VERSION ""

NS_ :

BS_:

BU_: Tester BCM ECM ACC ICM
VAL_TABLE_ BrakeDecelRequestState 1 "Applied Brake" 0 "Do not Applied Brake" ;
VAL_TABLE_ ACCDriverInfoState 5 "ACC_Fault" 4 "Driver_Intervention_is_required" 3 "ACC_Active" 2 "ACC_Stanby" 1 "ACC_On" 0 "ACC_Off" ;
VAL_TABLE_ Brakeswitchstate 1 "Brake_switch_Pressed" 0 "Brake_switch_Not_pressed" ;
VAL_TABLE_ CruiseSwitchState 7 "None" 6 "Time_Gap-" 5 "Time_Gap+" 4 "Resume" 3 "Coast" 2 "Set/Accel" 1 "On" 0 "Off" ;

BO_ 1576 DiagRx: 8 ACC
 SG_ DiagRx : 0|8@1+ (1,0) [0|0] ""  Tester

BO_ 1568 DiagTx: 8 Tester
 SG_ DiagTx : 0|8@1+ (1,0) [0|0] "" Vector__XXX

BO_ 359 BCM_Info: 1 BCM
 SG_ VehicleSpeed : 0|8@1+ (1,0) [0|0] "Km/hr"  ICM,ECM,ACC

BO_ 645 ECM_Info: 1 ECM
 SG_ BrakeSwitch2 : 0|1@1+ (1,0) [0|0] ""  ACC

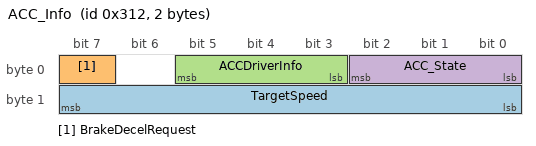
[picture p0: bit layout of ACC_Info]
BO_ 786 ACC_Info: 2 ACC
 SG_ TargetSpeed : 8|8@1+ (1,0) [0|0] "km/hr"  ECM
 SG_ BrakeDecelRequest : 7|1@1+ (1,0) [0|0] ""  BCM
 SG_ ACCDriverInfo : 3|3@1+ (1,0) [0|0] ""  ICM
 SG_ ACC_State : 0|3@1+ (1,0) [0|0] ""  ECM,BCM

BO_ 288 ICM_Info: 1 ICM
 SG_ CruiseSwitchRequest : 1|3@1+ (1,0) [0|7] ""  ACC
 SG_ BrakeSwitch1 : 0|1@1+ (1,0) [0|0] ""  ACC

BA_DEF_ BU_  "NmStationAddress" HEX 0 0;
BA_DEF_  "NmBaseAddress" HEX 0 0;
BA_DEF_ BU_  "NodeLayerModules" STRING ;
BA_DEF_ BU_  "ILUsed" ENUM  "No","Yes","vector_leerstring";
BA_DEF_ BO_  "GenMsgCycleTime" INT 0 0;
BA_DEF_ BO_  "GenMsgSendType" ENUM  "Cyclic","Event","Cyclic+Event";
BA_DEF_ SG_  "GenSigStartValue" INT 0 0;
BA_DEF_  "BusType" STRING ;
BA_DEF_DEF_  "NmStationAddress" 0;
BA_DEF_DEF_  "NmBaseAddress" 1280;
BA_DEF_DEF_  "NodeLayerModules" "CANoeILNLVector.dll";
BA_DEF_DEF_  "ILUsed" "Yes";
BA_DEF_DEF_  "GenMsgCycleTime" 50;
BA_DEF_DEF_  "GenMsgSendType" "Cyclic";
BA_DEF_DEF_  "GenSigStartValue" 0;
BA_DEF_DEF_  "BusType" "CAN";
BA_ "NodeLayerModules" BU_ Tester "CANoeILNLVector.dll,OSEK_TP.dll";
BA_ "NodeLayerModules" BU_ BCM "CANoeILNLVector.dll,OSEKNM01.dll";
BA_ "NmStationAddress" BU_ BCM 2;
BA_ "NodeLayerModules" BU_ ECM "CANoeILNLVector.dll,OSEKNM01.dll";
BA_ "NmStationAddress" BU_ ECM 3;
BA_ "NodeLayerModules" BU_ ACC "CANoeILNLVector.dll,OSEK_TP.dll,OSEKNM01.dll";
BA_ "NmStationAddress" BU_ ACC 1;
BA_ "NodeLayerModules" BU_ ICM "CANoeILNLVector.dll,OSEKNM01.dll";
BA_ "NmStationAddress" BU_ ICM 4;
BA_ "GenMsgCycleTime" BO_ 1576 0;
BA_ "GenMsgSendType" BO_ 1576 1;
BA_ "GenMsgSendType" BO_ 1568 2;
BA_ "GenMsgCycleTime" BO_ 1568 0;
BA_ "GenMsgCycleTime" BO_ 359 100;
BA_ "GenMsgCycleTime" BO_ 645 150;
BA_ "GenMsgCycleTime" BO_ 786 250;
BA_ "GenMsgCycleTime" BO_ 288 100;
BA_ "GenSigStartValue" SG_ 288 CruiseSwitchRequest 7;
VAL_ 645 BrakeSwitch2 1 "Brake_switch_Pressed" 0 "Brake_switch_Not_pressed" ;
VAL_ 786 BrakeDecelRequest 1 "Applied Brake" 0 "Do not Applied Brake" ;
VAL_ 786 ACCDriverInfo 5 "ACC_Fault" 4 "Driver_Intervention_is_required" 3 "ACC_Active" 2 "ACC_Stanby" 1 "ACC_On" 0 "ACC_Off" ;
VAL_ 786 ACC_State 5 "ACC_Fault" 4 "Driver_Intervention_is_required" 3 "ACC_Active" 2 "ACC_Stanby" 1 "ACC_On" 0 "ACC_Off" ;
VAL_ 288 CruiseSwitchRequest 7 "None" 6 "Time_Gap-" 5 "Time_Gap+" 4 "Resume" 3 "Coast" 2 "Set/Accel" 1 "On" 0 "Off" ;
VAL_ 288 BrakeSwitch1 1 "Brake_switch_Pressed" 0 "Brake_switch_Not_pressed" ;
